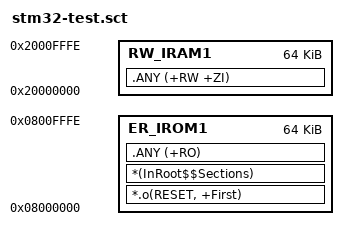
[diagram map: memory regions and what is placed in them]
LR_IROM1 0x08000000 0x0000FFFF  {    ; load region size_region
  ER_IROM1 0x08000000 0x0000FFFF  {  ; load address = execution address
   *.o(RESET, +First)
   *(InRoot$$Sections)
   .ANY (+RO)
  }
  RW_IRAM1 0x20000000 0x0000FFFF  {  ; RW data
   .ANY (+RW +ZI)
  }
}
